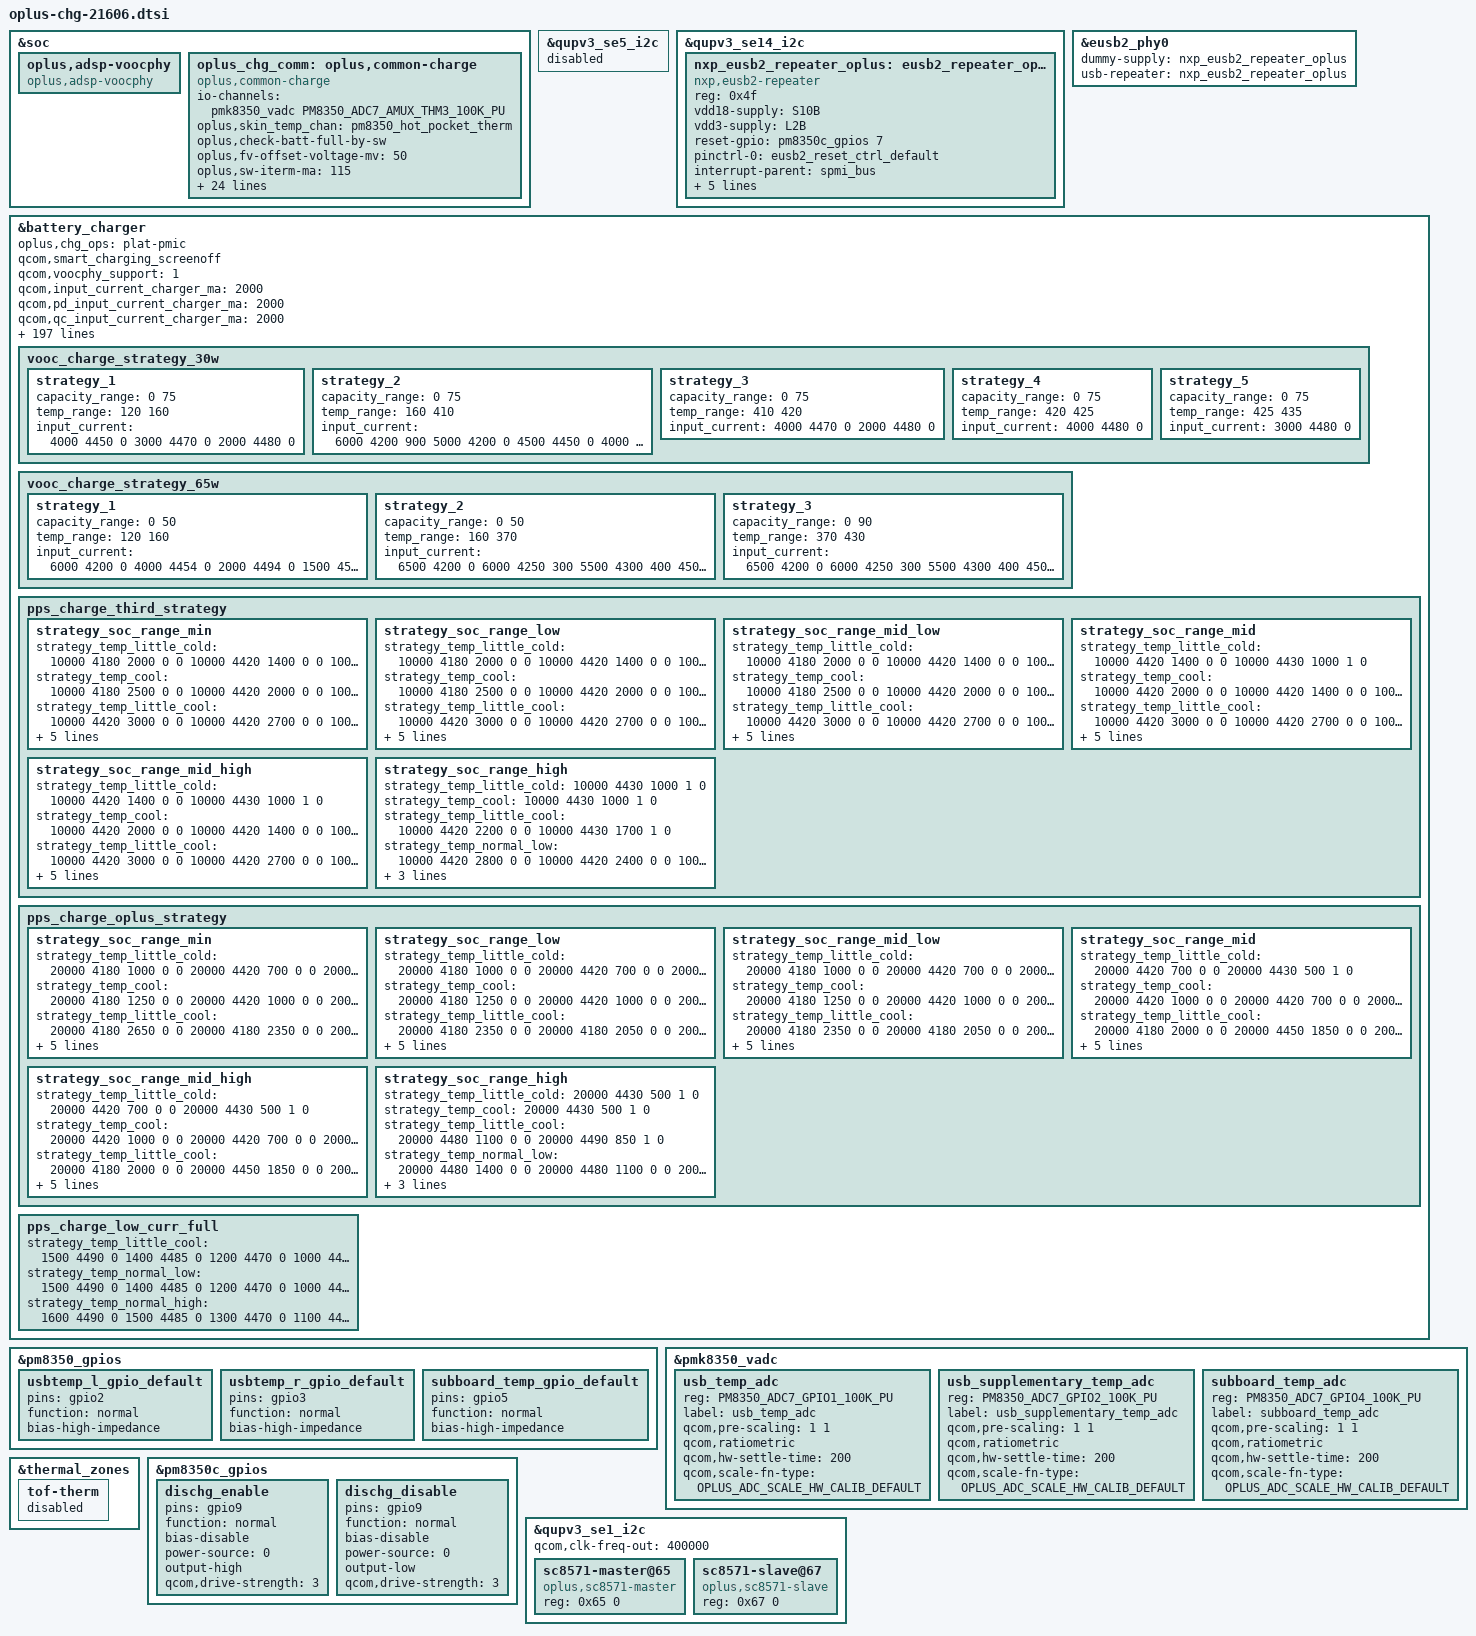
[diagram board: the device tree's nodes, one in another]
//ifdef OPLUS_FEATURE_CHG_BASIC

#include "oplus_chg_21606.h"

&soc {
	oplus,adsp-voocphy {
		compatible = "oplus,adsp-voocphy";
	};
};

&qupv3_se5_i2c {
	status = "disabled";
};

&qupv3_se14_i2c {

	status = "ok";

	#address-cells = <1>;
	#size-cells = <0>;
	nxp_eusb2_repeater_oplus: eusb2_repeater_oplus@4f {
		compatible = "nxp,eusb2-repeater";
		reg = <0x4f>;
		vdd18-supply = <&S10B>;
		vdd3-supply = <&L2B>;
		reset-gpio = <&pm8350c_gpios 7 GPIO_ACTIVE_HIGH>;
		pinctrl-names = "default";
		pinctrl-0 = <&eusb2_reset_ctrl_default>;
		interrupt-parent = <&spmi_bus>;
		interrupts = <0x2 0x8e 0x0 IRQ_TYPE_EDGE_RISING>;
		interrupt-names = "eusb2_rptr_reset_gpio_irq";
		qcom,param-override-seq-host = <0x63 0x8
						0x00 0x7
						0x50 0x6>;
		qcom,param-override-seq = <0x63 0x8
					   0x00 0x7
					   0x50 0x6>;
	};
};

&eusb2_phy0 {
	dummy-supply = <&nxp_eusb2_repeater_oplus>;
	usb-repeater = <&nxp_eusb2_repeater_oplus>;
};

&battery_charger {
	//for oplus chg framework:
	oplus,chg_ops = "plat-pmic";
	qcom,smart_charging_screenoff;
	qcom,voocphy_support = <1>;
	qcom,input_current_charger_ma = <2000>;
	qcom,pd_input_current_charger_ma = <2000>;
	qcom,qc_input_current_charger_ma = <2000>;

	qcom,input_current_usb_ma = <500>;

	qcom,input_current_cdp_ma = <1500>;
	qcom,input_current_led_ma = <1200>;
	qcom,input_current_led_ma_high = <1200>;
	qcom,input_current_led_ma_warm = <1500>;
	qcom,input_current_led_ma_normal = <2000>;
	qcom,led_warm_bat_decidegc = <350>;
	qcom,led_high_bat_decidegc = <370>;

	qcom,input_current_camera_ma = <1200>;

	qcom,input_current_vooc_led_ma_high = <2200>;
	qcom,input_current_vooc_led_ma_warm = <3200>;
	qcom,input_current_vooc_led_ma_normal = <3600>;
	qcom,input_current_vooc_ma_normal = <3600>;
	qcom,vooc_temp_bat_normal_decidegc = <350>;
	qcom,input_current_vooc_ma_warm = <3200>;
	qcom,vooc_temp_bat_warm_decidegc = <370>;
	qcom,input_current_vooc_ma_high = <2200>;
	qcom,vooc_temp_bat_hot_decidegc = <440>;

	qcom,charger_current_vooc_ma_normal = <1800>;

	qcom,chg_ctrl_by_calling;
	qcom,input_current_calling_ma = <1500>;

	//qcom,input_current_led_ma_overtemp = <900>;
	qcom,overtemp_bat_decidegc = <350>;
	qcom,iterm_disabled = <0>;
	qcom,iterm_ma = <130>;
	qcom,recharge-mv = <100>;
	qcom,batt_capacity_mah = <5000>;/*typical capacity*/
	//qcom,batt_capacity_mah = <4400>; /*rated capacity*/

	qcom,removed_bat_decidegc = <390>;  /*<-39C*/

	qcom,cold_bat_decidegc = <200>;  /*-10C~0C*/
	qcom,temp_cold_vfloat_mv = <4435>;
	qcom,temp_cold_fastchg_current_ma = <300>;

	qcom,little_cold_bat_decidegc = <0>;	/*0C~5C*/
	qcom,temp_little_cold_vfloat_mv = <4435>;
	qcom,temp_little_cold_fastchg_current_ma_high = <1100>;
	qcom,temp_little_cold_fastchg_current_ma_low = <1100>;
	qcom,temp_little_cold_fastchg_current_ma = <1100>;
	qcom,pd_temp_little_cold_fastchg_current_ma_high = <2000>;
	qcom,pd_temp_little_cold_fastchg_current_ma_low = <1600>;
	qcom,qc_temp_little_cold_fastchg_current_ma_high = <2000>;
	qcom,qc_temp_little_cold_fastchg_current_ma_low = <1600>;

	qcom,cool_bat_decidegc = <50>;	/*5C~12C*/
	qcom,temp_cool_vfloat_mv = <4435>;
	qcom,temp_cool_fastchg_current_ma_high = <1100>;
	qcom,temp_cool_fastchg_current_ma_low = <1100>;
	qcom,pd_temp_cool_fastchg_current_ma_high = <2000>;
	qcom,pd_temp_cool_fastchg_current_ma_low = <2000>;
	qcom,qc_temp_cool_fastchg_current_ma_high = <2000>;
	qcom,qc_temp_cool_fastchg_current_ma_low = <2000>;

	qcom,little_cool_bat_decidegc = <120>;	/*12C~16C*/
	qcom,temp_little_cool_vfloat_mv = <4435>;
	qcom,temp_little_cool_fastchg_current_ma = <1100>;
	qcom,pd_temp_little_cool_fastchg_current_ma = <2000>;
	qcom,qc_temp_little_cool_fastchg_current_ma = <2000>;

	qcom,normal_bat_decidegc = <160>;	/*16C~44C*/
	qcom,temp_normal_fastchg_current_ma = <1100>;
	qcom,temp_normal_vfloat_mv = <4435>;
	qcom,pd_temp_normal_fastchg_current_ma = <2000>;
	qcom,qc_temp_normal_fastchg_current_ma = <2000>;

	qcom,warm_bat_decidegc = <450>;		/*45C~53C*/ /*8pin Bat Vooc project need add 3 degree C*/
	qcom,temp_warm_vfloat_mv = <4130>;
	qcom,temp_warm_fastchg_current_ma = <700>;
	qcom,pd_temp_warm_fastchg_current_ma = <700>;
	qcom,qc_temp_warm_fastchg_current_ma = <700>;
	qcom,temp_warm_fastchg_current_ma_led_on = <300>;

	qcom,hot_bat_decidegc = <530>;

	qcom,non_standard_vfloat_mv = <3980>;
	qcom,non_standard_fastchg_current_ma = <512>;

	qcom,short_c_bat_cv_mv = <4330>;
	qcom,short_c_bat_vfloat_mv = <3800>;
	qcom,short_c_bat_fastchg_current_ma = <512>;

	qcom,cold_vfloat_sw_limit = <4385>;
	qcom,little_cold_vfloat_sw_limit = <4385>;
	qcom,cool_vfloat_sw_limit = <4385>;
	qcom,little_cool_vfloat_sw_limit = <4385>;
	qcom,normal_vfloat_sw_limit = <4385>;
	qcom,warm_vfloat_sw_limit = <4080>;
	qcom,non_standard_vfloat_sw_limit = <3930>;
	qcom,short_c_bat_vfloat_sw_limit = <3750>;

	qcom,max_chg_time_sec = <36000>;
	qcom,charger_hv_thr = <9900>;
	qcom,charger_recv_thr = <9500>;
	qcom,charger_lv_thr = <3400>;
	qcom,vbatt_full_thr = <4435>;
	qcom,vbatt_hv_thr = <4600>;
	qcom,vfloat_step_mv = <8>;
	qcom,non_standard_vfloat_over_sw_limit = <3990>;
	qcom,cold_vfloat_over_sw_limit = <4445>;
	qcom,little_cold_vfloat_over_sw_limit = <4445>;
	qcom,cool_vfloat_over_sw_limit = <4445>;
	qcom,little_cool_vfloat_over_sw_limit = <4445>;
	qcom,normal_vfloat_over_sw_limit = <4445>;
	qcom,warm_vfloat_over_sw_limit = <4140>;

	qcom,vbatt_power_off = <3300>;
	qcom,vbatt_soc_1 = <3310>;
	qcom,vooc_project = <9>;
	qcom,vbatt_num = <2>;
	qcom,ffc_support;
	qcom,dual_ffc;
	qcom,nightstandby_support;
	recharge_after_full;
	//qcom,wireless_support;
	//qcom,wpc_no_chargerpump;

	qcom,normal_vterm_hw_inc = <18>;
	qcom,non_normal_vterm_hw_inc = <18>;

	qcom,ff1_normal_fastchg_ma = <550>;
	qcom,ff1_warm_fastchg_ma = <550>;
	qcom,ffc2_normal_fastchg_ma = <350>;/*12C~35c*/
	qcom,ffc2_temp_warm_decidegc = <350>;
	qcom,ffc2_warm_fastchg_ma = <400>;/*35C~40c*/
	qcom,ffc2_temp_high_decidegc = <400>;
	qcom,ffc2_temp_low_decidegc = <120>;
	qcom,ffc2_exit_step_ma = <150>;
	qcom,ff1_exit_step_ma = <150>;
	qcom,ff1_warm_exit_step_ma = <150>;

	qcom,ffc_normal_vfloat_sw_limit = <4445>;
	qcom,ffc2_normal_vfloat_sw_limit = <4440>;
	qcom,ffc2_warm_vfloat_sw_limit = <4440>;
	qcom,ffc_temp_normal_vfloat_mv = <4500>;
	qcom,ffc1_temp_normal_vfloat_mv = <4500>;
	qcom,ffc2_temp_normal_vfloat_mv = <4500>;
	qcom,ffc_normal_vfloat_over_sw_limit = <4500>;
	qcom,ffc1_normal_vfloat_over_sw_limit = <4500>;
	qcom,ffc2_normal_vfloat_over_sw_limit = <4500>;

	qcom,default_iterm_ma = <130>;
	qcom,default_temp_normal_fastchg_current_ma = <1100>;
	qcom,default_normal_vfloat_sw_limit = <4385>;
	qcom,default_temp_normal_vfloat_mv = <4435>;
	qcom,default_normal_vfloat_over_sw_limit = <4445>;

	qcom,default_temp_little_cool_fastchg_current_ma = <1100>;
	qcom,default_little_cool_vfloat_sw_limit = <4385>;
	qcom,default_temp_little_cool_vfloat_mv = <4435>;
	qcom,default_little_cool_vfloat_over_sw_limit = <4445>;

	qcom,fg_info_package_read_support;/*for oplus_chg_get_props_from_adsp_by_buffer() to read*/

	///qcom,offset_temp = <30>;
	//for control:
	//qcom,suspend_after_full;
	qcom,check_batt_full_by_sw;
	qcom,external_gauge;
	qcom,chg_ctrl_by_lcd;
	qcom,chg_ctrl_by_vooc;
	qcom,chg_ctrl_by_camera;
	qcom,sw_vfloat_over_protect_enable;
	qcom,usbtemp_batttemp_gap = <12>;
	qcom,usbtemp_change_gap;

	//for PD9V or QC9V
	//qcom,vbatt_pdqc_to_5v_thr = <4100>;
	qcom,vbatt_pdqc_to_9v_thr = <5000>;/*always 9v*/
	qcom,vooc_show_ui_soc_decimal;
	qcom,ui_soc_decimal_speedmin = <20>;//2A
	qcom,otg_scheme = <0>;//0:cid 1:ccdetect_gpio 2:switch
	qcom,otg_boost_src = <0>;//0:plat_pmic 1:external

	qcom,dischg-gpio = <&pm8350c_gpios 9 0x00>;
	pinctrl-names = "dischg_enable", "dischg_disable",
					"usbtemp_l_gpio_default", "usbtemp_r_gpio_default",
					"subboard_temp_gpio_default";
	pinctrl-0 = <&dischg_enable>;
	pinctrl-1 = <&dischg_disable>;
	pinctrl-2 = <&usbtemp_l_gpio_default>;
	pinctrl-3 = <&usbtemp_r_gpio_default>;
	pinctrl-4 = <&subboard_temp_gpio_default>;
        
	//qcom,pps_30w_num = <9>;
	oplus,pps_ops = "cp-sc8571";
	qcom,pps_support_type = <2>;
	qcom,pps_warm_allow_vol = <4000>;
	qcom,pps_warm_allow_soc = <50>;
	qcom,pps_strategy_normal_current = <8000>;//6A
	qcom,pps_over_high_or_low_current = <8000>;
	qcom,pps_full_cool_sw_vbat = <4430>;
	qcom,pps_full_normal_sw_vbat = <4490>;
	qcom,pps_full_normal_hw_vbat = <4500>;
	qcom,pps_full_ffc_vbat = <4420>;
	qcom,pps_warm_full_voltage = <4130>;
	qcom,pps_full_cool_sw_vbat_30w = <4430>;
	qcom,pps_full_normal_sw_vbat_30w = <4430>;
	qcom,pps_full_normal_hw_vbat_30w = <4440>;
	oplus,pps_r_default = <120 10 10 15 15 15 15>;
	oplus,pps_rmos_mohm = <4>;
	oplus,pps_r_limit = <280 200 140 90 50>;
	oplus,pps_strategy_batt_high_temp = <425 430 435 400 415 420>;
	oplus,pps_strategy_high_current = <8000 8000 8000 8000 8000 8000>;
	oplus,pps_charge_strategy_soc = <0 15 35 55 75 85 95>;
	oplus,pps_charge_strategy_temp = <0 50 120 200 350 440 510>;
	oplus,pps_low_curr_full_strategy_temp = <120 200 350 440>;
	
	qcom,vooc-max-input-volt-support = <10000>;     //10V
	qcom,vooc-max-input-current-support = <6500>;   //6.5A
	vooc_charge_strategy_30w {
		strategy_1 {
			capacity_range = <0 75>;
			temp_range = <120 160>;
			input_current = <4000 4450 0
					3000 4470 0
					2000 4480 0>;
			};
		strategy_2 {
			capacity_range = <0 75>;
			temp_range = <160 410>;
			input_current = <6000 4200 900
					5000 4200 0
					4500 4450 0
					4000 4450 0
					3000 4470 0
					2000 4480 0>;
		};
		strategy_3 {
			capacity_range = <0 75>;
			temp_range = <410 420>;
			input_current = <4000 4470 0
					2000 4480 0>;
		};
		strategy_4 {
			capacity_range = <0 75>;
			temp_range = <420 425>;
			input_current = <4000 4480 0>;
		};
		strategy_5 {
			capacity_range = <0 75>;
			temp_range = <425 435>;
			input_current = <3000 4480 0>;
		};
	};

	vooc_charge_strategy_65w {
		strategy_1 {
			capacity_range = <0 50>;
			temp_range = <120 160>;
			input_current = <6000 4200 0
					4000 4454 0
					2000 4494 0
					1500 4500 0>;
		};
		strategy_2 {
			capacity_range = <0 50>;
			temp_range = <160 370>;
			input_current = <6500 4200 0
					6000 4250 300
					5500 4300 400
					4500 4454 780
					3500 4454 0
					2000 4494 0
					1500 4500 0>;
		};
		strategy_3 {
			capacity_range = <0 90>;
			temp_range = <370 430>;
			input_current = <6500 4200 0
					6000 4250 300
					5500 4300 400
					4500 4454 780
					3500 4454 0
					2000 4494 0
					1600 4500 0>;
		};
	};

	pps_charge_third_strategy {
		strategy_soc_range_min {
			strategy_temp_little_cold =	<10000 4180 2000 0 0
							 10000 4420 1400 0 0
							 10000 4430 1000 1 0>;
			strategy_temp_cool =		<10000 4180 2500 0 0
							 10000 4420 2000 0 0
							 10000 4420 1400 0 0
							 10000 4430 1000 1 0>;
			strategy_temp_little_cool =	<10000 4420 3000 0 0
							 10000 4420 2700 0 0
							 10000 4420 2400 0 0
							 10000 4420 2100 0 0
							 10000 4430 1700 1 0>;
			strategy_temp_normal_low =	<10000 4420 3000 0 0
							 10000 4420 2700 0 0
							 10000 4420 2400 0 0
							 10000 4420 2100 0 0
							 10000 4430 1700 1 0>;
			strategy_temp_normal_high =	<10000 4420 3000 0 0
							 10000 4420 2700 0 0
							 10000 4420 2400 0 0
							 10000 4420 2100 0 0
							 10000 4430 1800 1 0>;
			strategy_temp_warm =		<10000 4130 1200 1 0>;
		};
		strategy_soc_range_low {
			strategy_temp_little_cold =	<10000 4180 2000 0 0
							 10000 4420 1400 0 0
							 10000 4430 1000 1 0>;
			strategy_temp_cool =		<10000 4180 2500 0 0
							 10000 4420 2000 0 0
							 10000 4420 1400 0 0
							 10000 4430 1000 1 0>;
			strategy_temp_little_cool =	<10000 4420 3000 0 0
							 10000 4420 2700 0 0
							 10000 4420 2400 0 0
							 10000 4420 2100 0 0
							 10000 4430 1700 1 0>;
			strategy_temp_normal_low =	<10000 4420 3000 0 0
							 10000 4420 2700 0 0
							 10000 4420 2400 0 0
							 10000 4420 2100 0 0
							 10000 4430 1700 1 0>;
			strategy_temp_normal_high =	<10000 4420 3000 0 0
							 10000 4420 2700 0 0
							 10000 4420 2400 0 0
							 10000 4420 2100 0 0
							 10000 4430 1800 1 0>;
			strategy_temp_warm =		<10000 4130 1200 1 0>;
		};
		strategy_soc_range_mid_low {
			strategy_temp_little_cold =	<10000 4180 2000 0 0
							 10000 4420 1400 0 0
							 10000 4430 1000 1 0>;
			strategy_temp_cool =		<10000 4180 2500 0 0
							 10000 4420 2000 0 0
							 10000 4420 1400 0 0
							 10000 4430 1000 1 0>;
			strategy_temp_little_cool =	<10000 4420 3000 0 0
							 10000 4420 2700 0 0
							 10000 4420 2400 0 0
							 10000 4420 2100 0 0
							 10000 4430 1700 1 0>;
			strategy_temp_normal_low =	<10000 4420 3000 0 0
							 10000 4420 2700 0 0
							 10000 4420 2400 0 0
							 10000 4420 2100 0 0
							 10000 4430 1700 1 0>;
			strategy_temp_normal_high =	<10000 4420 3000 0 0
							 10000 4420 2700 0 0
							 10000 4420 2400 0 0
							 10000 4420 2100 0 0
							 10000 4430 1800 1 0>;
			strategy_temp_warm =		<10000 4130 1200 1 0>;
		};
		strategy_soc_range_mid {
			strategy_temp_little_cold =	<10000 4420 1400 0 0
							 10000 4430 1000 1 0>;
			strategy_temp_cool =		<10000 4420 2000 0 0
							 10000 4420 1400 0 0
							 10000 4430 1000 1 0>;
			strategy_temp_little_cool =	<10000 4420 3000 0 0
							 10000 4420 2700 0 0
							 10000 4420 2400 0 0
							 10000 4420 2100 0 0
							 10000 4430 1700 1 0>;
			strategy_temp_normal_low =	<10000 4420 3000 0 0
							 10000 4420 2700 0 0
							 10000 4420 2400 0 0
							 10000 4420 2100 0 0
							 10000 4430 1700 1 0>;
			strategy_temp_normal_high =	<10000 4420 3000 0 0
							 10000 4420 2700 0 0
							 10000 4420 2400 0 0
							 10000 4420 2100 0 0
							 10000 4430 1800 1 0>;
			strategy_temp_warm =		<10000 4130 1200 1 0>;
		};
		strategy_soc_range_mid_high {
			strategy_temp_little_cold =	<10000 4420 1400 0 0
							 10000 4430 1000 1 0>;
			strategy_temp_cool =		<10000 4420 2000 0 0
							 10000 4420 1400 0 0
							 10000 4430 1000 1 0>;
			strategy_temp_little_cool =	<10000 4420 3000 0 0
							 10000 4420 2700 0 0
							 10000 4420 2400 0 0
							 10000 4420 2100 0 0
							 10000 4430 1700 1 0>;
			strategy_temp_normal_low =	<10000 4420 3000 0 0
							 10000 4420 2700 0 0
							 10000 4420 2400 0 0
							 10000 4420 2100 0 0
							 10000 4430 1700 1 0>;
			strategy_temp_normal_high =	<10000 4420 3000 0 0
							 10000 4420 2700 0 0
							 10000 4420 2400 0 0
							 10000 4420 2100 0 0
							 10000 4430 1800 1 0>;
			strategy_temp_warm =		<10000 4130 1200 1 0>;
		};
		strategy_soc_range_high {
			strategy_temp_little_cold =	<10000 4430 1000 1 0>;
			strategy_temp_cool =		<10000 4430 1000 1 0>;
			strategy_temp_little_cool =	<10000 4420 2200 0 0
							 10000 4430 1700 1 0>;
			strategy_temp_normal_low =	<10000 4420 2800 0 0
							 10000 4420 2400 0 0
							 10000 4420 2100 0 0
							 10000 4430 1700 1 0>;
			strategy_temp_normal_high =	<10000 4420 2800 0 0
							 10000 4420 2400 0 0
							 10000 4420 2100 0 0
							 10000 4430 1800 1 0>;
			strategy_temp_warm =		<10000 4130 1200 1 0>;
		};
	};

	pps_charge_oplus_strategy {
		strategy_soc_range_min {
			strategy_temp_little_cold =	<20000 4180 1000 0 0
							 20000 4420 700 0 0
							 20000 4430 500 1 0>;
			strategy_temp_cool =		<20000 4180 1250 0 0
							 20000 4420 1000 0 0
							 20000 4420 700 0 0
							 20000 4430 500 1 0>;
			strategy_temp_little_cool =	<20000 4180 2650 0 0
							 20000 4180 2350 0 0
							 20000 4180 2050 0 0
							 20000 4450 1850 0 0
							 20000 4450 1550 0 0
							 20000 4480 1400 0 0
							 20000 4480 1100 0 0
							 20000 4490 850 1 0>;
			strategy_temp_normal_low =	<20000 4150 7500 0 0
							 20000 4150 6000 0 0
							 20000 4250 4000 0 0
							 20000 4250 3700 0 0
							 20000 4250 3400 0 0
							 20000 4400 3300 0 0
							 20000 4400 3000 0 0
							 20000 4400 2700 0 0
							 20000 4400 2400 0 0
							 20000 4480 2300 0 0
							 20000 4480 2000 0 0
							 20000 4480 1700 0 0
							 20000 4480 1400 0 0
							 20000 4480 1100 0 0
							 20000 4490 850 1 0>;
			strategy_temp_normal_high =	<20000 4150 7500 0 0
							 20000 4150 6000 0 0
							 20000 4250 4000 0 0
							 20000 4250 3700 0 0
							 20000 4250 3400 0 0
							 20000 4400 3300 0 0
							 20000 4400 3000 0 0
							 20000 4400 2700 0 0
							 20000 4400 2400 0 0
							 20000 4480 2300 0 0
							 20000 4480 2000 0 0
							 20000 4480 1700 0 0
							 20000 4480 1400 0 0
							 20000 4480 1100 0 0
							 20000 4490 900 1 0>;
			strategy_temp_warm =		<20000 4130 600 1 0>;
		};
		strategy_soc_range_low {
			strategy_temp_little_cold =	<20000 4180 1000 0 0
							 20000 4420 700 0 0
							 20000 4430 500 1 0>;
			strategy_temp_cool =		<20000 4180 1250 0 0
							 20000 4420 1000 0 0
							 20000 4420 700 0 0
							 20000 4430 500 1 0>;
			strategy_temp_little_cool =	<20000 4180 2350 0 0
							 20000 4180 2050 0 0
							 20000 4450 1850 0 0
							 20000 4450 1550 0 0
							 20000 4480 1400 0 0
							 20000 4480 1100 0 0
							 20000 4490 850 1 0>;
			strategy_temp_normal_low =	<20000 4160 5000 0 0
							 20000 4250 4000 0 0
							 20000 4250 3700 0 0
							 20000 4250 3400 0 0
							 20000 4400 3300 0 0
							 20000 4400 3000 0 0
							 20000 4400 2700 0 0
							 20000 4400 2400 0 0
							 20000 4480 2300 0 0
							 20000 4480 2000 0 0
							 20000 4480 1700 0 0
							 20000 4480 1400 0 0
							 20000 4480 1100 0 0
							 20000 4490 850 1 0>;
			strategy_temp_normal_high =	<20000 4160 5000 0 0
							 20000 4250 4000 0 0
							 20000 4250 3700 0 0
							 20000 4250 3400 0 0
							 20000 4400 3300 0 0
							 20000 4400 3000 0 0
							 20000 4400 2700 0 0
							 20000 4400 2400 0 0
							 20000 4480 2300 0 0
							 20000 4480 2000 0 0
							 20000 4480 1700 0 0
							 20000 4480 1400 0 0
							 20000 4480 1100 0 0
							 20000 4490 900 1 0>;
			strategy_temp_warm =		<20000 4130 600 1 0>;
		};
		strategy_soc_range_mid_low {
			strategy_temp_little_cold =	<20000 4180 1000 0 0
							 20000 4420 700 0 0
							 20000 4430 500 1 0>;
			strategy_temp_cool =		<20000 4180 1250 0 0
							 20000 4420 1000 0 0
							 20000 4420 700 0 0
							 20000 4430 500 1 0>;
			strategy_temp_little_cool =	<20000 4180 2350 0 0
							 20000 4180 2050 0 0
							 20000 4450 1850 0 0
							 20000 4450 1550 0 0
							 20000 4480 1400 0 0
							 20000 4480 1100 0 0
							 20000 4490 850 1 0>;
			strategy_temp_normal_low =	<20000 4250 4000 0 0
							 20000 4250 3700 0 0
							 20000 4250 3400 0 0
							 20000 4400 3300 0 0
							 20000 4400 3000 0 0
							 20000 4400 2700 0 0
							 20000 4400 2400 0 0
							 20000 4480 2300 0 0
							 20000 4480 2000 0 0
							 20000 4480 1700 0 0
							 20000 4480 1400 0 0
							 20000 4480 1100 0 0
							 20000 4490 850 1 0>;
			strategy_temp_normal_high =	<20000 4250 4000 0 0
							 20000 4250 3700 0 0
							 20000 4250 3400 0 0
							 20000 4400 3300 0 0
							 20000 4400 3000 0 0
							 20000 4400 2700 0 0
							 20000 4400 2400 0 0
							 20000 4480 2300 0 0
							 20000 4480 2000 0 0
							 20000 4480 1700 0 0
							 20000 4480 1400 0 0
							 20000 4480 1100 0 0
							 20000 4490 900 1 0>;
			strategy_temp_warm =		<20000 4130 600 1 0>;
		};
		strategy_soc_range_mid {
			strategy_temp_little_cold =	<20000 4420 700 0 0
							 20000 4430 500 1 0>;
			strategy_temp_cool =		<20000 4420 1000 0 0
							 20000 4420 700 0 0
							 20000 4430 500 1 0>;
			strategy_temp_little_cool =	<20000 4180 2000 0 0
							 20000 4450 1850 0 0
							 20000 4450 1550 0 0
							 20000 4480 1400 0 0
							 20000 4480 1100 0 0
							 20000 4490 850 1 0>;
			strategy_temp_normal_low =	<20000 4400 3000 0 0
							 20000 4400 2700 0 0
							 20000 4400 2400 0 0
							 20000 4480 2300 0 0
							 20000 4480 2000 0 0
							 20000 4480 1700 0 0
							 20000 4480 1400 0 0
							 20000 4480 1100 0 0
							 20000 4490 850 1 0>;
			strategy_temp_normal_high =	<20000 4400 3300 0 0
							 20000 4400 3000 0 0
							 20000 4400 2700 0 0
							 20000 4400 2400 0 0
							 20000 4480 2300 0 0
							 20000 4480 2000 0 0
							 20000 4480 1700 0 0
							 20000 4480 1400 0 0
							 20000 4480 1100 0 0
							 20000 4490 900 1 0>;
			strategy_temp_warm =		<20000 4130 600 1 0>;
		};
		strategy_soc_range_mid_high {
			strategy_temp_little_cold =	<20000 4420 700 0 0
							 20000 4430 500 1 0>;
			strategy_temp_cool =		<20000 4420 1000 0 0
							 20000 4420 700 0 0
							 20000 4430 500 1 0>;
			strategy_temp_little_cool =	<20000 4180 2000 0 0
							 20000 4450 1850 0 0
							 20000 4450 1550 0 0
							 20000 4480 1400 0 0
							 20000 4480 1100 0 0
							 20000 4490 850 1 0>;
			strategy_temp_normal_low =	<20000 4480 2000 0 0
							 20000 4480 1700 0 0
							 20000 4480 1400 0 0
							 20000 4480 1100 0 0
							 20000 4490 850 1 0>;
			strategy_temp_normal_high =	<20000 4480 2300 0 0
							 20000 4480 2000 0 0
							 20000 4480 1700 0 0
							 20000 4480 1400 0 0
							 20000 4480 1100 0 0
							 20000 4490 900 1 0>;
			strategy_temp_warm =		<20000 4130 600 1 0>;
		};
		strategy_soc_range_high {
			strategy_temp_little_cold =	<20000 4430 500 1 0>;
			strategy_temp_cool =		<20000 4430 500 1 0>;
			strategy_temp_little_cool =	<20000 4480 1100 0 0
							 20000 4490 850 1 0>;
			strategy_temp_normal_low =	<20000 4480 1400 0 0
							 20000 4480 1100 0 0
							 20000 4490 850 1 0>;
			strategy_temp_normal_high =	<20000 4480 1400 0 0
							 20000 4480 1100 0 0
							 20000 4490 900 1 0>;
			strategy_temp_warm =		<20000 4130 600 1 0>;
		};
	};

	pps_charge_low_curr_full {
		strategy_temp_little_cool = 	<1500 4490 0
						 1400 4485 0
						 1200 4470 0
						 1000 4460 0
						 800 4450 1>;
		strategy_temp_normal_low =	<1500 4490 0
						 1400 4485 0
						 1200 4470 0
						 1000 4460 0
						 800 4450 1>;
		strategy_temp_normal_high = 	<1600 4490 0
						 1500 4485 0
						 1300 4470 0
						 1100 4460 0
						 900 4450 1>;
	};
};

&pm8350_gpios {
	usbtemp_l_gpio_default: usbtemp_l_gpio_default {
		pins = "gpio2"; /* GPIO 2 */
		function = "normal"; /* normal */
		bias-high-impedance; /* DISABLE GPIO2 for ADC*/
	};
	usbtemp_r_gpio_default: usbtemp_r_gpio_default {
		pins = "gpio3"; /* GPIO 3 */
		function = "normal"; /* normal */
		bias-high-impedance; /* DISABLE GPIO3 for ADC*/
	};
	subboard_temp_gpio_default: subboard_temp_gpio_default {
		pins = "gpio5"; /* GPIO 5 */
		function = "normal"; /* normal */
		bias-high-impedance; /* DISABLE GPIO5 for ADC*/
    };
};

&pmk8350_vadc {
	usb_temp_adc {
		reg = <PM8350_ADC7_GPIO1_100K_PU>;
		label = "usb_temp_adc";
		qcom,pre-scaling = <1 1>;
		qcom,ratiometric;
		qcom,hw-settle-time = <200>;
		qcom,scale-fn-type = <OPLUS_ADC_SCALE_HW_CALIB_DEFAULT>;
	};
	usb_supplementary_temp_adc {
		reg = <PM8350_ADC7_GPIO2_100K_PU>;
		label = "usb_supplementary_temp_adc";
		qcom,pre-scaling = <1 1>;
		qcom,ratiometric;
		qcom,hw-settle-time = <200>;
		qcom,scale-fn-type = <OPLUS_ADC_SCALE_HW_CALIB_DEFAULT>;
	};
	subboard_temp_adc {
		reg = <PM8350_ADC7_GPIO4_100K_PU>;
		label = "subboard_temp_adc";
		qcom,pre-scaling = <1 1>;
		qcom,ratiometric;
		qcom,hw-settle-time = <200>;
		qcom,scale-fn-type = <OPLUS_ADC_SCALE_HW_CALIB_DEFAULT>;
	};
};

&battery_charger {
	io-channels	= <&pmk8350_vadc PM8350_ADC7_GPIO1_100K_PU>,
					<&pmk8350_vadc PM8350_ADC7_GPIO2_100K_PU>,
					<&pmk8350_vadc PM8350_ADC7_GPIO4_100K_PU>;
	io-channel-names = "usb_temp_adc",
						"usb_supplementary_temp_adc",
						"subboard_temp_adc";
};

&thermal_zones {
	tof-therm {
		status = "disabled";
	};
};

&pm8350c_gpios {
	dischg_enable: dischg_enable {
		pins = "gpio9"; /* GPIO 9 */
		function = "normal"; /* normal */
		bias-disable; //No Pull
		power-source = <0>;//VIN0 3.3
		output-high; //digital output, no invert
		qcom,drive-strength = <3>; //LOW strength
		//drive-push-pull;//CMOS
	};

	dischg_disable: dischg_disable {
		pins = "gpio9"; /* GPIO 9 */
		function = "normal"; /* normal */
		bias-disable; //No Pull
		power-source = <0>;//VIN0 3.3
		output-low; //digital output, no invert
		qcom,drive-strength = <3>; //LOW strength
		//drive-push-pull;//CMOS
	};
};
//#endif OPLUS_FEATURE_CHG_BASIC

//wireless support, 21613 not use, just for chg framework support
&battery_charger {
	oplus,ic_type = <OPLUS_CHG_IC_BUCK>;
	oplus,ic_index = <0>;
};

&soc {
	oplus_chg_comm: oplus,common-charge {
		status = "ok";
		compatible = "oplus,common-charge";

		io-channels = <&pmk8350_vadc PM8350_ADC7_AMUX_THM3_100K_PU>;
		io-channel-names = "pm8350_hot_pocket_therm";

		oplus,skin_temp_chan = "pm8350_hot_pocket_therm";

		oplus,check-batt-full-by-sw;
		oplus,fv-offset-voltage-mv = <50>;
		oplus,sw-iterm-ma = <115>;
		oplus,full-count-sw-num = <2>;
		oplus,batt-uv-mv = <2500>;
		oplus,batt-ov-mv = <4950>;
		oplus,batt-oc-ma = <6500>;
		oplus,batt-ovd-mv = <1000>;
		oplus,batt-curr-limit-thr-mv = <4180>;

		oplus,batt-them-thr = <(-20) 0 50 120 400 450 530>;//tbat
		oplus,vbatmax-mv = <0 3980 4435 4435 4435 4435 4130 0>;//fv
		oplus,ffc-temp-thr = <120 350 400>;
		oplus,usb-ffc-step-max = <1>;
		oplus,usb-ffc-fv-mv = <4500>;
		oplus,usb-ffc-fv-cutoff-mv = <4445>;
		oplus,usb-ffc-fcc-ma = <350 400>;
		oplus,usb-ffc-fcc-cutoff-ma = <300 350>;
		oplus,wls-ffc-step-max = <2>;
		oplus,wls-ffc-fv-mv = <4500 4500>;
		oplus,wls-ffc-fv-cutoff-mv = <4445 4435>;
		oplus,wls-ffc-icl-ma = <800 800
					550  550>;
		oplus,wls-ffc-fcc-ma = <550 550
					350 350>;
		oplus,wls-ffc-fcc-cutoff-ma = <400 400
					       200 200>;
		oplus,wls-vbatdet-mv = <0 3675 4235 4370 4370 4370 4030 0>;
	};
};

&qupv3_se1_i2c {
	status = "ok";
	qcom,clk-freq-out = <400000>;

	sc8571-master@65 {
		status = "okay";
		compatible = "oplus,sc8571-master";
		reg = <0x65 0>;
	};

	sc8571-slave@67 {
		status = "okay";
		compatible = "oplus,sc8571-slave";
		reg = <0x67 0>;
	};
};
//endif OPLUS_FEATURE_CHG_BASIC
